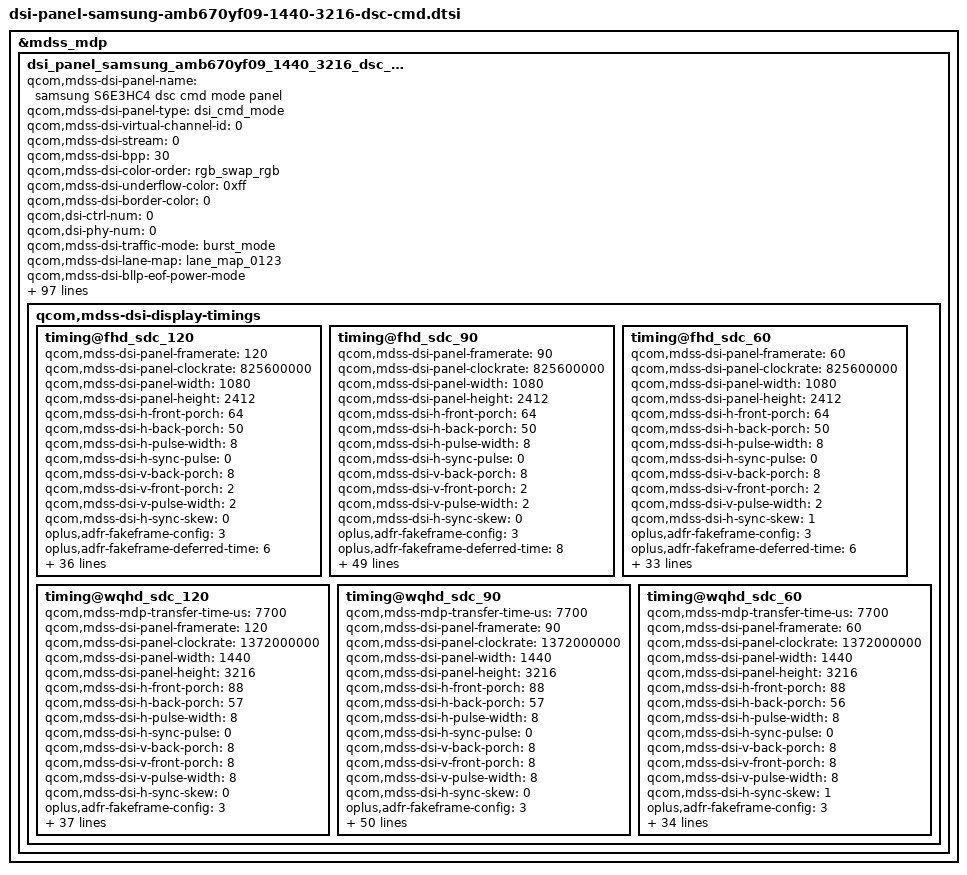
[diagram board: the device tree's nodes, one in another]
&mdss_mdp {
	dsi_panel_samsung_amb670yf09_1440_3216_dsc_cmd: qcom,mdss_dsi_panel_samsung_amb670yf09_1440_3216_dsc_cmd {
		qcom,mdss-dsi-panel-name = "samsung S6E3HC4 dsc cmd mode panel";
		qcom,mdss-dsi-panel-type = "dsi_cmd_mode";
		qcom,mdss-dsi-virtual-channel-id = <0>;
		qcom,mdss-dsi-stream = <0>;
		qcom,mdss-dsi-bpp = <30>;
		qcom,mdss-dsi-color-order = "rgb_swap_rgb";
		qcom,mdss-dsi-underflow-color = <0xff>;
		qcom,mdss-dsi-border-color = <0>;
		qcom,dsi-ctrl-num = <0>;
		qcom,dsi-phy-num = <0>;
		qcom,mdss-dsi-traffic-mode = "burst_mode";
		qcom,mdss-dsi-lane-map = "lane_map_0123";
		qcom,mdss-dsi-bllp-eof-power-mode;
		qcom,mdss-dsi-bllp-power-mode;
		qcom,mdss-dsi-lane-0-state;
		qcom,mdss-dsi-lane-1-state;
		qcom,mdss-dsi-lane-2-state;
		qcom,mdss-dsi-lane-3-state;
		qcom,mdss-dsi-dma-trigger = "trigger_sw";
		qcom,mdss-dsi-mdp-trigger = "none";
		qcom,mdss-dsi-reset-sequence = <1 10>, <0 5>, <1 10>;
		qcom,mdss-pan-physical-width-dimension = <73>;
		qcom,mdss-pan-physical-height-dimension = <160>;
		qcom,mdss-dsi-te-check-enable;
		qcom,mdss-dsi-te-using-te-pin;
		qcom,mdss-dsi-te-pin-select = <1>;
		qcom,mdss-dsi-te-dcs-command = <1>;
		qcom,mdss-dsi-wr-mem-start = <0x2C>;
		qcom,mdss-dsi-wr-mem-continue = <0x3C>;
		//qcom,mdss-dsi-lp11-init;
		qcom,mdss-dsi-init-delay-us = <1000>;
		qcom,mdss-dsi-panel-jitter = <0x4 0x1>;
		qcom,dynamic-mode-switch-enabled;
		qcom,dynamic-mode-switch-type = "dynamic-resolution-switch-immediate";
		/* HDR Setting */
		qcom,mdss-dsi-panel-hdr-enabled;
		qcom,mdss-dsi-panel-hdr-color-primaries = <15635 16450 34000 16000 13250 34500 7500 3000>;
		qcom,mdss-dsi-panel-peak-brightness = <5400000>;
		qcom,mdss-dsi-panel-average-brightness = <2000000>;
		qcom,mdss-dsi-panel-blackness-level = <2000>;

		qcom,mdss-dsi-display-timings {
			timing@fhd_sdc_120 {
				#include "dsi-panel-samsung-amb670yf09-1440-3216-dsc-cmd-common.dtsi"
				//qcom,mdss-mdp-transfer-time-us = <6000>;
				qcom,mdss-dsi-panel-framerate = <120>;
				qcom,mdss-dsi-panel-clockrate = <825600000>;
				qcom,mdss-dsi-panel-width = <1080>;
				qcom,mdss-dsi-panel-height = <2412>;
				qcom,mdss-dsi-h-front-porch = <64>;
				qcom,mdss-dsi-h-back-porch = <50>;
				qcom,mdss-dsi-h-pulse-width = <8>;
				qcom,mdss-dsi-h-sync-pulse = <0>;
				qcom,mdss-dsi-v-back-porch = <8>;
				qcom,mdss-dsi-v-front-porch = <2>;
				qcom,mdss-dsi-v-pulse-width = <2>;

				/* SDC ADFR */
				qcom,mdss-dsi-h-sync-skew = <0>;
				oplus,adfr-fakeframe-config = <3>;
				oplus,adfr-fakeframe-deferred-time = <6>;		/* period*0.7 */
				qcom,mdss-dsi-qsync-min-fps-0 = <1314>;
				qcom,mdss-dsi-qsync-min-fps-1 = <1314>;
				qcom,mdss-dsi-fakeframe-command = [
					05 00 00 40 00 00 01 2C
					05 00 00 40 00 00 01 3C
					05 00 00 40 00 00 01 2C
					05 00 00 40 00 00 01 3C
					05 00 00 00 00 00 01 00
				];

				qcom,mdss-dsi-timing-switch-command = [
					/* CASET/PASET Setting */
					39 00 00 00 00 00 05 2A 00 00 04 37
					39 00 00 00 00 00 05 2B 00 00 09 6B
					/* Scaler Setting */
					39 00 00 40 00 00 03 F0 5A 5A
					15 00 00 40 00 00 02 C3 89
					39 00 00 00 00 00 03 F0 A5 A5

					/* TSP_SYNC1 Fixed Setting */
					39 00 00 40 00 00 03 F0 5A 5A
					39 00 00 40 00 00 04 B0 00 3C B9
					39 00 00 40 00 00 03 B9 19 09
					39 00 00 40 00 00 04 B0 00 40 B9
					39 00 00 40 00 00 03 B9 33 33					/* TSP_VSYNC 0x33, 0x33 : Fixed TE; 0x30, 0x30 : G TE */
					39 00 00 40 00 00 04 B0 00 05 F2
					15 00 00 40 00 00 02 F2 C9
					15 00 00 40 00 00 02 F7 0F
					39 00 00 00 00 00 03 F0 A5 A5
					/* TSP_SYNC3 Fixed Setting */
					39 00 00 40 00 00 03 F0 5A 5A
					39 00 00 40 00 00 04 B0 00 06 F2
					15 00 00 40 00 00 02 F2 41
					39 00 00 40 00 00 04 B0 00 3E B9
					15 00 00 40 00 00 02 B9 09
					39 00 00 40 00 00 04 B0 00 42 B9
					15 00 00 40 00 00 02 B9 03
					39 00 00 40 00 00 04 B0 00 46 B9
					15 00 00 40 00 00 02 B9 00
					15 00 00 40 00 00 02 F7 0F
					39 00 00 00 79 00 03 F0 A5 A5
					/* Fixed TE Setting */
					39 00 00 40 00 00 03 F0 5A 5A
					15 00 00 40 00 00 02 B9 51
					39 00 00 40 00 00 04 B0 00 02 B9
					15 00 00 40 00 00 02 B9 00
					39 00 00 40 00 00 04 B0 00 08 B9
					39 00 00 40 00 00 09 B9 00 00 00 01 00 00 00 01
					39 00 00 00 79 00 03 F0 A5 A5

					/* 90hz Transition */
					39 00 00 40 00 00 03 F0 5A 5A
					15 00 00 40 00 00 02 AB 83
					39 00 00 40 00 00 04 B0 00 01 BD
					15 00 00 40 00 00 02 BD 02
					39 00 00 40 00 00 04 B0 00 08 F2
					39 00 00 40 00 00 04 F2 1C 00 14
					15 00 00 40 00 00 02 60 00
					15 00 00 40 00 00 02 F7 0F
					39 00 00 00 00 00 03 F0 A5 A5

					/* 120hz Transition */
					39 00 00 40 00 00 03 F0 5A 5A
					39 00 00 40 00 00 04 B0 00 17 F2
					39 00 00 40 00 00 03 F2 01 B5
					39 00 00 40 00 00 03 BD 21 02
					15 00 00 40 00 00 02 60 00
					39 00 00 40 00 00 04 B0 00 8C 94
					39 00 00 40 00 00 1F 94
						08 40 08 29 07 E2 07 B6
						07 53 06 EC 06 65 05 DB
						05 54 04 CD 04 4A 03 7C
						01 5E 01 5E 01 5E
					15 00 00 40 00 00 02 BD 23
					39 00 00 40 00 00 04 B0 00 10 BD
					15 00 00 40 00 00 02 BD 00
					39 00 00 40 00 00 04 B0 00 16 BD
					15 00 00 40 00 00 02 BD FF
					39 00 00 40 00 00 04 B0 00 14 BD
					15 00 00 40 00 00 02 BD 00
					15 00 00 40 00 00 02 F7 0F
					39 00 00 00 00 00 03 F0 A5 A5
				];
				qcom,mdss-dsi-on-command = [
					/* DSC Setting */
					39 00 00 00 00 00 5A 9E
						12 00 00 AB 30 80 09 6C
						04 38 00 24 02 1C 02 1C
						02 00 02 3B 00 20 03 35
						00 07 00 0E 03 34 02 D4
						18 00 10 F0 07 10 20 00
						06 0F 0F 33 0E 1C 2A 38
						46 54 62 69 70 77 79 7B
						7D 7E 02 02 22 00 2A 40
						2A BE 3A FC 3A FA 3A F8
						3B 38 3B 78 3B B6 4B B6
						4B F4 4B F4 6C 34 84 74
						00
					15 00 00 00 00 00 02 9D 01

					/* Sleep Out(11h) */
					05 00 00 00 06 00 01 11

					/* TSP_SYNC1 Fixed Setting */
					39 00 00 40 00 00 03 F0 5A 5A
					39 00 00 40 00 00 04 B0 00 3C B9
					39 00 00 40 00 00 03 B9 19 09
					39 00 00 40 00 00 04 B0 00 40 B9
					39 00 00 40 00 00 03 B9 33 33					/* TSP_VSYNC 0x33, 0x33 : Fixed TE; 0x30, 0x30 : G TE */
					39 00 00 40 00 00 04 B0 00 05 F2
					15 00 00 40 00 00 02 F2 C9
					15 00 00 40 00 00 02 F7 0F
					39 00 00 00 00 00 03 F0 A5 A5
					/* TSP_SYNC3 Fixed Setting */
					39 00 00 40 00 00 03 F0 5A 5A
					39 00 00 40 00 00 04 B0 00 06 F2
					15 00 00 40 00 00 02 F2 41
					39 00 00 40 00 00 04 B0 00 3E B9
					15 00 00 40 00 00 02 B9 09
					39 00 00 40 00 00 04 B0 00 42 B9
					15 00 00 40 00 00 02 B9 03
					39 00 00 40 00 00 04 B0 00 46 B9
					15 00 00 40 00 00 02 B9 00
					15 00 00 40 00 00 02 F7 0F
					39 00 00 00 79 00 03 F0 A5 A5
					/* Fixed TE Setting */
					39 00 00 40 00 00 03 F0 5A 5A
					15 00 00 40 00 00 02 B9 51
					39 00 00 40 00 00 04 B0 00 02 B9
					15 00 00 40 00 00 02 B9 00
					39 00 00 40 00 00 04 B0 00 08 B9
					39 00 00 40 00 00 09 B9 00 00 00 01 00 00 00 01
					39 00 00 00 79 00 03 F0 A5 A5

					/* 90hz Transition */
					39 00 00 40 00 00 03 F0 5A 5A
					15 00 00 40 00 00 02 AB 83
					39 00 00 40 00 00 04 B0 00 01 BD
					15 00 00 40 00 00 02 BD 02
					39 00 00 40 00 00 04 B0 00 08 F2
					39 00 00 40 00 00 04 F2 1C 00 14
					15 00 00 40 00 00 02 60 00
					15 00 00 40 00 00 02 F7 0F
					39 00 00 00 00 00 03 F0 A5 A5

					/* 120hz Transition */
					39 00 00 40 00 00 03 F0 5A 5A
					39 00 00 40 00 00 04 B0 00 17 F2
					39 00 00 40 00 00 03 F2 01 B5
					39 00 00 40 00 00 03 BD 21 02
					15 00 00 40 00 00 02 60 00
					39 00 00 40 00 00 04 B0 00 8C 94
					39 00 00 40 00 00 1F 94
						08 40 08 29 07 E2 07 B6
						07 53 06 EC 06 65 05 DB
						05 54 04 CD 04 4A 03 7C
						01 5E 01 5E 01 5E
					15 00 00 40 00 00 02 BD 23
					39 00 00 40 00 00 04 B0 00 10 BD
					15 00 00 40 00 00 02 BD 00
					39 00 00 40 00 00 04 B0 00 16 BD
					15 00 00 40 00 00 02 BD FF
					39 00 00 40 00 00 04 B0 00 14 BD
					15 00 00 40 00 00 02 BD 00
					15 00 00 40 00 00 02 F7 0F
					39 00 00 00 00 00 03 F0 A5 A5

					/* Common Setting */
					39 00 00 40 00 00 03 F0 5A 5A
					39 00 00 40 00 00 03 F2 00 01					/* FQ_CON Setting */
					39 00 00 00 00 00 03 F0 A5 A5
					/* TE(Vsync) ON */
					39 00 00 40 00 00 03 F0 5A 5A
					15 00 00 40 00 00 02 35 00
					39 00 00 00 00 00 03 F0 A5 A5
					/* CASET/PASET Setting */
					39 00 00 00 00 00 05 2A 00 00 04 37
					39 00 00 00 00 00 05 2B 00 00 09 6B
					/* Scaler Setting */
					39 00 00 40 00 00 03 F0 5A 5A
					15 00 00 40 00 00 02 C3 89
					39 00 00 00 00 00 03 F0 A5 A5
					/* DCDC setting of AOD Sequence */
					39 00 00 40 00 00 03 F0 5A 5A
					39 00 00 40 00 00 04 B0 00 18 B1
					15 00 00 40 00 00 02 B1 05
					39 00 00 00 00 00 03 F0 A5 A5

					/* Brightness Control */
					39 00 00 40 00 00 03 F0 5A 5A
					39 00 00 40 00 00 04 B0 00 10 94
					15 00 00 40 00 00 02 94 01
					39 00 00 40 00 00 04 B0 00 0F 94
					15 00 00 40 00 00 02 94 90
					39 00 00 40 00 00 03 F0 A5 A5
					15 00 00 40 00 00 02 53 28
					15 00 00 00 00 00 02 F7 0F
					/* ACL Mode */
					39 00 00 40 00 00 03 F0 5A 5A
					39 00 00 40 00 00 04 B0 00 01 94
					15 00 00 40 00 00 02 94 0D
					15 00 00 40 00 00 02 55 00
					39 00 00 00 00 00 03 F0 A5 A5
					/* OPEC Setting */
					39 00 00 40 00 00 03 F0 5A 5A
					39 00 00 40 00 00 04 B0 00 1D 63
					15 00 00 40 00 00 02 63 02
					39 00 00 00 00 00 03 F0 A5 A5
					/* Display On */
					05 00 00 00 00 00 01 29
				];

				qcom,mdss-dsi-qsync-on-commands = [
					/* SDC Auto On */
					39 00 00 40 00 00 03 F0 5A 5A
					15 00 00 40 00 00 02 BD 23
					39 00 00 40 00 00 04 B0 00 10 BD
					15 00 00 40 00 00 02 BD 10
					39 00 00 40 00 00 04 B0 00 16 BD
					15 00 00 40 00 00 02 BD 03
					15 00 00 40 00 00 02 F7 0F
					39 00 00 00 00 00 03 F0 A5 A5
				];
				qcom,mdss-dsi-qsync-off-commands = [
					/* SDC Auto Off */
					39 00 00 40 00 00 03 F0 5A 5A
					15 00 00 40 00 00 02 BD 23
					39 00 00 40 00 00 04 B0 00 10 BD
					15 00 00 40 00 00 02 BD 00
					39 00 00 40 00 00 04 B0 00 16 BD
					15 00 00 40 00 00 02 BD FF
					15 00 00 40 00 00 02 F7 0F
					39 00 00 00 00 00 03 F0 A5 A5
				];
				qcom,mdss-dsi-qsync-min-fps-0-command = [
					/* SDC Auto Off */
					39 00 00 40 00 00 03 F0 5A 5A
					39 00 00 40 00 00 04 B0 00 14 BD
					15 00 00 40 00 00 02 BD 00
					39 00 00 40 00 00 04 B0 00 13 BD
					15 00 00 40 00 00 02 BD 00
					15 00 00 40 00 00 02 F7 0F
					39 00 00 00 00 00 03 F0 A5 A5
				];
				qcom,mdss-dsi-qsync-min-fps-1-command = [
					/* SDC Auto On */
					39 00 00 40 00 00 03 F0 5A 5A
					39 00 00 40 00 00 04 B0 00 14 BD
					15 00 00 40 00 00 02 BD 00
					39 00 00 40 00 00 04 B0 00 13 BD
					15 00 00 40 00 00 02 BD 00
					15 00 00 40 00 00 02 F7 0F
					39 00 00 00 00 00 03 F0 A5 A5
				];

				qcom,mdss-dsi-fakeframe-command-state = "dsi_hs_mode";
				qcom,mdss-dsi-qsync-on-commands-state ="dsi_hs_mode";
				qcom,mdss-dsi-qsync-off-commands-state ="dsi_hs_mode";
				qcom,mdss-dsi-qsync-min-fps-0-command-state = "dsi_hs_mode";
				qcom,mdss-dsi-qsync-min-fps-1-command-state = "dsi_hs_mode";
				qcom,panel-roi-alignment=<1080 36 1080 36 1080 36>;
				qcom,partial-update-enabled = "single_roi";

				qcom,lm-split = <540 540>;
				qcom,mdss-dsc-slice-height = <36>;
				qcom,mdss-dsc-slice-width = <540>;
			};

			timing@fhd_sdc_90 {
				//qcom,mdss-mdp-transfer-time-us = <6000>;
				qcom,mdss-dsi-panel-framerate = <90>;
				qcom,mdss-dsi-panel-clockrate = <825600000>;
				qcom,mdss-dsi-panel-width = <1080>;
				qcom,mdss-dsi-panel-height = <2412>;
				qcom,mdss-dsi-h-front-porch = <64>;
				qcom,mdss-dsi-h-back-porch = <50>;
				qcom,mdss-dsi-h-pulse-width = <8>;
				qcom,mdss-dsi-h-sync-pulse = <0>;
				qcom,mdss-dsi-v-back-porch = <8>;
				qcom,mdss-dsi-v-front-porch = <2>;
				qcom,mdss-dsi-v-pulse-width = <2>;

				/* SDC ADFR */
				qcom,mdss-dsi-h-sync-skew = <0>;
				oplus,adfr-fakeframe-config = <3>;
				oplus,adfr-fakeframe-deferred-time = <8>;		/* period*0.7 */
				qcom,mdss-dsi-qsync-min-fps-0 = <1314>;
				qcom,mdss-dsi-qsync-min-fps-1 = <1314>;
				qcom,mdss-dsi-fakeframe-command = [
					05 00 00 40 00 00 01 2C
					05 00 00 40 00 00 01 3C
					05 00 00 40 00 00 01 2C
					05 00 00 40 00 00 01 3C
					05 00 00 00 00 00 01 00
				];

				qcom,mdss-dsi-adfr-pre-switch-command = [
					39 00 00 40 00 00 03 F0 5A 5A					/* Level2 key Access Enable */
					39 00 00 40 00 00 04 B0 00 14 BD
					15 00 00 40 00 00 02 BD 00						/* SDC auto mode min == max */
					15 00 00 40 00 00 02 BD 23						/* 21 : Manual On  23 Auto On */
					15 00 00 40 00 00 02 F7 0F
					39 00 00 00 00 00 03 F0 A5 A5					/* Level2 key Access Disable */
				];

				qcom,mdss-dsi-timing-switch-command = [
					/* CASET/PASET Setting */
					39 00 00 00 00 00 05 2A 00 00 04 37
					39 00 00 00 00 00 05 2B 00 00 09 6B
					/* Scaler Setting */
					39 00 00 40 00 00 03 F0 5A 5A
					15 00 00 40 00 00 02 C3 89
					39 00 00 00 00 00 03 F0 A5 A5

					/* TSP_SYNC1 Fixed Setting */
					39 00 00 40 00 00 03 F0 5A 5A
					39 00 00 40 00 00 04 B0 00 3C B9
					39 00 00 40 00 00 03 B9 19 09
					39 00 00 40 00 00 04 B0 00 40 B9
					39 00 00 40 00 00 03 B9 33 33					/* TSP_VSYNC 0x33, 0x33 : Fixed TE; 0x30, 0x30 : G TE */
					39 00 00 40 00 00 04 B0 00 05 F2
					15 00 00 40 00 00 02 F2 C9
					15 00 00 40 00 00 02 F7 0F
					39 00 00 00 00 00 03 F0 A5 A5
					/* TSP_SYNC3 Fixed Setting */
					39 00 00 40 00 00 03 F0 5A 5A
					39 00 00 40 00 00 04 B0 00 06 F2
					15 00 00 40 00 00 02 F2 41
					39 00 00 40 00 00 04 B0 00 3E B9
					15 00 00 40 00 00 02 B9 09
					39 00 00 40 00 00 04 B0 00 42 B9
					15 00 00 40 00 00 02 B9 03
					39 00 00 40 00 00 04 B0 00 46 B9
					15 00 00 40 00 00 02 B9 00
					15 00 00 40 00 00 02 F7 0F
					39 00 00 00 79 00 03 F0 A5 A5

					/* 120hz Transition */
					39 00 00 40 00 00 03 F0 5A 5A
					39 00 00 40 00 00 04 B0 00 17 F2
					39 00 00 40 00 00 03 F2 01 B5
					39 00 00 40 00 00 03 BD 21 02
					15 00 00 40 00 00 02 60 00
					39 00 00 40 00 00 04 B0 00 8C 94
					39 00 00 40 00 00 1F 94
						08 40 08 29 07 E2 07 B6
						07 53 06 EC 06 65 05 DB
						05 54 04 CD 04 4A 03 7C
						01 5E 01 5E 01 5E
					15 00 00 40 00 00 02 F7 0F
					39 00 00 00 00 00 03 F0 A5 A5

					/* 90hz Transition */
					39 00 00 40 00 00 03 F0 5A 5A
					15 00 00 40 00 00 02 AB 83
					39 00 00 40 00 00 04 B0 00 01 BD
					15 00 00 40 00 00 02 BD 03
					39 00 00 40 00 00 04 B0 00 08 F2
					39 00 00 40 00 00 04 F2 1C 04 54
					15 00 00 40 00 00 02 60 08
					15 00 00 40 00 00 02 F7 0F
					39 00 00 00 00 00 03 F0 A5 A5
				];
				qcom,mdss-dsi-on-command = [
					/* DSC Setting */
					39 00 00 00 00 00 5A 9E
						12 00 00 AB 30 80 09 6C
						04 38 00 24 02 1C 02 1C
						02 00 02 3B 00 20 03 35
						00 07 00 0E 03 34 02 D4
						18 00 10 F0 07 10 20 00
						06 0F 0F 33 0E 1C 2A 38
						46 54 62 69 70 77 79 7B
						7D 7E 02 02 22 00 2A 40
						2A BE 3A FC 3A FA 3A F8
						3B 38 3B 78 3B B6 4B B6
						4B F4 4B F4 6C 34 84 74
						00
					15 00 00 00 00 00 02 9D 01

					/* Sleep Out(11h) */
					05 00 00 00 06 00 01 11

					/* TSP_SYNC1 Fixed Setting */
					39 00 00 40 00 00 03 F0 5A 5A
					39 00 00 40 00 00 04 B0 00 3C B9
					39 00 00 40 00 00 03 B9 19 09
					39 00 00 40 00 00 04 B0 00 40 B9
					39 00 00 40 00 00 03 B9 33 33					/* TSP_VSYNC 0x33, 0x33 : Fixed TE; 0x30, 0x30 : G TE */
					39 00 00 40 00 00 04 B0 00 05 F2
					15 00 00 40 00 00 02 F2 C9
					15 00 00 40 00 00 02 F7 0F
					39 00 00 00 00 00 03 F0 A5 A5
					/* TSP_SYNC3 Fixed Setting */
					39 00 00 40 00 00 03 F0 5A 5A
					39 00 00 40 00 00 04 B0 00 06 F2
					15 00 00 40 00 00 02 F2 41
					39 00 00 40 00 00 04 B0 00 3E B9
					15 00 00 40 00 00 02 B9 09
					39 00 00 40 00 00 04 B0 00 42 B9
					15 00 00 40 00 00 02 B9 03
					39 00 00 40 00 00 04 B0 00 46 B9
					15 00 00 40 00 00 02 B9 00
					15 00 00 40 00 00 02 F7 0F
					39 00 00 00 79 00 03 F0 A5 A5

					/* 120hz Transition */
					39 00 00 40 00 00 03 F0 5A 5A
					39 00 00 40 00 00 04 B0 00 17 F2
					39 00 00 40 00 00 03 F2 01 B5
					39 00 00 40 00 00 03 BD 21 02
					15 00 00 40 00 00 02 60 00
					39 00 00 40 00 00 04 B0 00 8C 94
					39 00 00 40 00 00 1F 94
						08 40 08 29 07 E2 07 B6
						07 53 06 EC 06 65 05 DB
						05 54 04 CD 04 4A 03 7C
						01 5E 01 5E 01 5E
					15 00 00 40 00 00 02 F7 0F
					39 00 00 00 00 00 03 F0 A5 A5

					/* 90hz Transition */
					39 00 00 40 00 00 03 F0 5A 5A
					15 00 00 40 00 00 02 AB 83
					39 00 00 40 00 00 04 B0 00 01 BD
					15 00 00 40 00 00 02 BD 03
					39 00 00 40 00 00 04 B0 00 08 F2
					39 00 00 40 00 00 04 F2 1C 04 54
					15 00 00 40 00 00 02 60 08
					15 00 00 40 00 00 02 F7 0F
					39 00 00 00 00 00 03 F0 A5 A5

					/* Common Setting */
					39 00 00 40 00 00 03 F0 5A 5A
					39 00 00 40 00 00 03 F2 00 01					/* FQ_CON Setting */
					39 00 00 00 00 00 03 F0 A5 A5
					/* TE(Vsync) ON */
					39 00 00 40 00 00 03 F0 5A 5A
					15 00 00 40 00 00 02 35 00
					39 00 00 00 00 00 03 F0 A5 A5
					/* CASET/PASET Setting */
					39 00 00 00 00 00 05 2A 00 00 04 37
					39 00 00 00 00 00 05 2B 00 00 09 6B
					/* Scaler Setting */
					39 00 00 40 00 00 03 F0 5A 5A
					15 00 00 40 00 00 02 C3 89
					39 00 00 00 00 00 03 F0 A5 A5
					/* DCDC setting of AOD Sequence */
					39 00 00 40 00 00 03 F0 5A 5A
					39 00 00 40 00 00 04 B0 00 18 B1
					15 00 00 40 00 00 02 B1 05
					39 00 00 00 00 00 03 F0 A5 A5

					/* Brightness Control */
					39 00 00 40 00 00 03 F0 5A 5A
					39 00 00 40 00 00 04 B0 00 10 94
					15 00 00 40 00 00 02 94 01
					39 00 00 40 00 00 04 B0 00 0F 94
					15 00 00 40 00 00 02 94 90
					39 00 00 40 00 00 03 F0 A5 A5
					15 00 00 40 00 00 02 53 28
					15 00 00 00 00 00 02 F7 0F
					/* ACL Mode */
					39 00 00 40 00 00 03 F0 5A 5A
					39 00 00 40 00 00 04 B0 00 01 94
					15 00 00 40 00 00 02 94 0D
					15 00 00 40 00 00 02 55 00
					39 00 00 00 00 00 03 F0 A5 A5
					/* OPEC Setting */
					39 00 00 40 00 00 03 F0 5A 5A
					39 00 00 40 00 00 04 B0 00 1D 63
					15 00 00 40 00 00 02 63 02
					39 00 00 00 00 00 03 F0 A5 A5
					/* Display On */
					05 00 00 00 00 00 01 29
				];

				qcom,mdss-dsi-post-on-backlight = [
					/* Display On */
					05 00 00 00 00 00 01 29
				];
				qcom,mdss-dsi-off-command = [
					/* Display Off */
					05 00 00 00 15 00 02 28 00
					/* Sleep In */
					05 00 00 00 65 00 02 10 00
				];

				qcom,mdss-dsi-qsync-on-commands = [
				];
				qcom,mdss-dsi-qsync-off-commands = [
				];
				qcom,mdss-dsi-qsync-min-fps-0-command = [
				];
				qcom,mdss-dsi-qsync-min-fps-1-command = [
				];

				qcom,mdss-dsi-fakeframe-command-state = "dsi_hs_mode";
				qcom,mdss-dsi-adfr-pre-switch-command-state = "dsi_hs_mode";
				qcom,mdss-dsi-timing-switch-command-state = "dsi_hs_mode";
				qcom,mdss-dsi-qsync-on-commands-state ="dsi_hs_mode";
				qcom,mdss-dsi-qsync-off-commands-state ="dsi_hs_mode";
				qcom,mdss-dsi-qsync-min-fps-0-command-state = "dsi_hs_mode";
				qcom,mdss-dsi-qsync-min-fps-1-command-state = "dsi_hs_mode";
				qcom,panel-roi-alignment=<1080 36 1080 36 1080 36>;
				qcom,partial-update-enabled = "single_roi";

				qcom,compression-mode = "dsc";
				qcom,mdss-dsc-encoders = <2>;
				qcom,mdss-dsc-slice-per-pkt = <2>;
				qcom,mdss-dsc-bit-per-component = <10>;
				qcom,mdss-dsc-bit-per-pixel = <8>;
				qcom,mdss-dsc-version = <0x12>;
				//qcom,mdss-dsc-scr-version = <1>;
				qcom,mdss-dsc-block-prediction-enable;
				qcom,lm-split = <540 540>;
				qcom,mdss-dsc-slice-height = <36>;
				qcom,mdss-dsc-slice-width = <540>;
			};

			timing@fhd_sdc_60 {
				#include "dsi-panel-samsung-amb670yf09-1440-3216-dsc-60fps-cmd-common.dtsi"
				//qcom,mdss-mdp-transfer-time-us = <6000>;
				qcom,mdss-dsi-panel-framerate = <60>;
				qcom,mdss-dsi-panel-clockrate = <825600000>;
				qcom,mdss-dsi-panel-width = <1080>;
				qcom,mdss-dsi-panel-height = <2412>;
				qcom,mdss-dsi-h-front-porch = <64>;
				qcom,mdss-dsi-h-back-porch = <50>;
				qcom,mdss-dsi-h-pulse-width = <8>;
				qcom,mdss-dsi-h-sync-pulse = <0>;
				qcom,mdss-dsi-v-back-porch = <8>;
				qcom,mdss-dsi-v-front-porch = <2>;
				qcom,mdss-dsi-v-pulse-width = <2>;

				/* SDC ADFR */
				qcom,mdss-dsi-h-sync-skew = <1>;
				oplus,adfr-fakeframe-config = <3>;
				oplus,adfr-fakeframe-deferred-time = <6>;		/* period*0.7 */
				qcom,mdss-dsi-qsync-min-fps-0 = <1314>;
				qcom,mdss-dsi-qsync-min-fps-1 = <1314>;
				qcom,mdss-dsi-fakeframe-command = [
					05 00 00 40 00 00 01 2C
					05 00 00 40 00 00 01 3C
					05 00 00 40 00 00 01 2C
					05 00 00 40 00 00 01 3C
					05 00 00 00 00 00 01 00
				];

				qcom,mdss-dsi-timing-switch-command = [
					/* CASET/PASET Setting */
					39 00 00 00 00 00 05 2A 00 00 04 37
					39 00 00 00 00 00 05 2B 00 00 09 6B
					/* Scaler Setting */
					39 00 00 40 00 00 03 F0 5A 5A
					15 00 00 40 00 00 02 C3 89
					39 00 00 00 00 00 03 F0 A5 A5

					/* TSP_SYNC1 Fixed Setting */
					39 00 00 40 00 00 03 F0 5A 5A
					39 00 00 40 00 00 04 B0 00 3C B9
					39 00 00 40 00 00 03 B9 19 09
					39 00 00 40 00 00 04 B0 00 40 B9
					39 00 00 40 00 00 03 B9 33 33					/* TSP_VSYNC 0x33, 0x33 : Fixed TE; 0x30, 0x30 : G TE */
					39 00 00 40 00 00 04 B0 00 05 F2
					15 00 00 40 00 00 02 F2 C9
					15 00 00 40 00 00 02 F7 0F
					39 00 00 00 00 00 03 F0 A5 A5
					/* TSP_SYNC3 Fixed Setting */
					39 00 00 40 00 00 03 F0 5A 5A
					39 00 00 40 00 00 04 B0 00 06 F2
					15 00 00 40 00 00 02 F2 41
					39 00 00 40 00 00 04 B0 00 3E B9
					15 00 00 40 00 00 02 B9 09
					39 00 00 40 00 00 04 B0 00 42 B9
					15 00 00 40 00 00 02 B9 03
					39 00 00 40 00 00 04 B0 00 46 B9
					15 00 00 40 00 00 02 B9 01
					15 00 00 40 00 00 02 F7 0F
					39 00 00 00 79 00 03 F0 A5 A5
					/* Fixed TE Setting */
					39 00 00 40 00 00 03 F0 5A 5A
					15 00 00 40 00 00 02 B9 51
					39 00 00 40 00 00 04 B0 00 02 B9
					15 00 00 40 00 00 02 B9 01
					39 00 00 40 00 00 04 B0 00 08 B9
					39 00 00 40 00 00 09 B9 00 00 00 01 00 00 00 01
					39 00 00 00 79 00 03 F0 A5 A5

					/* 90hz Transition */
					39 00 00 40 00 00 03 F0 5A 5A
					15 00 00 40 00 00 02 AB 83
					39 00 00 40 00 00 04 B0 00 01 BD
					15 00 00 40 00 00 02 BD 02
					39 00 00 40 00 00 04 B0 00 08 F2
					39 00 00 40 00 00 04 F2 1C 00 14
					15 00 00 40 00 00 02 60 00
					15 00 00 40 00 00 02 F7 0F
					39 00 00 00 00 00 03 F0 A5 A5

					/* 60hz Transition */
					39 00 00 40 00 00 03 F0 5A 5A
					39 00 00 40 00 00 04 B0 00 17 F2
					39 00 00 40 00 00 03 F2 01 B5
					39 00 00 40 00 00 03 BD 21 02
					15 00 00 40 00 00 02 60 01
					39 00 00 40 00 00 04 B0 00 8C 94
					39 00 00 40 00 00 1F 94
						08 40 08 29 07 E2 07 B6
						07 53 06 EC 06 65 05 DB
						05 54 04 CD 04 4A 03 7C
						01 5E 01 5E 01 5E
					15 00 00 40 00 00 02 BD 23
					39 00 00 40 00 00 04 B0 00 10 BD
					15 00 00 40 00 00 02 BD 00
					39 00 00 40 00 00 04 B0 00 16 BD
					15 00 00 40 00 00 02 BD FF
					39 00 00 40 00 00 04 B0 00 14 BD
					15 00 00 40 00 00 02 BD 01
					15 00 00 40 00 00 02 F7 0F
					39 00 00 00 00 00 03 F0 A5 A5
				];
				qcom,mdss-dsi-on-command = [
					/* DSC Setting */
					39 00 00 00 00 00 5A 9E
						12 00 00 AB 30 80 09 6C
						04 38 00 24 02 1C 02 1C
						02 00 02 3B 00 20 03 35
						00 07 00 0E 03 34 02 D4
						18 00 10 F0 07 10 20 00
						06 0F 0F 33 0E 1C 2A 38
						46 54 62 69 70 77 79 7B
						7D 7E 02 02 22 00 2A 40
						2A BE 3A FC 3A FA 3A F8
						3B 38 3B 78 3B B6 4B B6
						4B F4 4B F4 6C 34 84 74
						00
					15 00 00 00 00 00 02 9D 01

					/* Sleep Out(11h) */
					05 00 00 00 06 00 01 11

					/* TSP_SYNC1 Fixed Setting */
					39 00 00 40 00 00 03 F0 5A 5A
					39 00 00 40 00 00 04 B0 00 3C B9
					39 00 00 40 00 00 03 B9 19 09
					39 00 00 40 00 00 04 B0 00 40 B9
					39 00 00 40 00 00 03 B9 33 33					/* TSP_VSYNC 0x33, 0x33 : Fixed TE; 0x30, 0x30 : G TE */
					39 00 00 40 00 00 04 B0 00 05 F2
					15 00 00 40 00 00 02 F2 C9
					15 00 00 40 00 00 02 F7 0F
					39 00 00 00 00 00 03 F0 A5 A5
					/* TSP_SYNC3 Fixed Setting */
					39 00 00 40 00 00 03 F0 5A 5A
					39 00 00 40 00 00 04 B0 00 06 F2
					15 00 00 40 00 00 02 F2 41
					39 00 00 40 00 00 04 B0 00 3E B9
					15 00 00 40 00 00 02 B9 09
					39 00 00 40 00 00 04 B0 00 42 B9
					15 00 00 40 00 00 02 B9 03
					39 00 00 40 00 00 04 B0 00 46 B9
					15 00 00 40 00 00 02 B9 01
					15 00 00 40 00 00 02 F7 0F
					39 00 00 00 79 00 03 F0 A5 A5
					/* Fixed TE Setting */
					39 00 00 40 00 00 03 F0 5A 5A
					15 00 00 40 00 00 02 B9 51
					39 00 00 40 00 00 04 B0 00 02 B9
					15 00 00 40 00 00 02 B9 01
					39 00 00 40 00 00 04 B0 00 08 B9
					39 00 00 40 00 00 09 B9 00 00 00 01 00 00 00 01
					39 00 00 00 79 00 03 F0 A5 A5

					/* 90hz Transition */
					39 00 00 40 00 00 03 F0 5A 5A
					15 00 00 40 00 00 02 AB 83
					39 00 00 40 00 00 04 B0 00 01 BD
					15 00 00 40 00 00 02 BD 02
					39 00 00 40 00 00 04 B0 00 08 F2
					39 00 00 40 00 00 04 F2 1C 00 14
					15 00 00 40 00 00 02 60 00
					15 00 00 40 00 00 02 F7 0F
					39 00 00 00 00 00 03 F0 A5 A5

					/* 60hz Transition */
					39 00 00 40 00 00 03 F0 5A 5A
					39 00 00 40 00 00 04 B0 00 17 F2
					39 00 00 40 00 00 03 F2 01 B5
					39 00 00 40 00 00 03 BD 21 02
					15 00 00 40 00 00 02 60 01
					39 00 00 40 00 00 04 B0 00 8C 94
					39 00 00 40 00 00 1F 94
						08 40 08 29 07 E2 07 B6
						07 53 06 EC 06 65 05 DB
						05 54 04 CD 04 4A 03 7C
						01 5E 01 5E 01 5E
					15 00 00 40 00 00 02 BD 23
					39 00 00 40 00 00 04 B0 00 10 BD
					15 00 00 40 00 00 02 BD 00
					39 00 00 40 00 00 04 B0 00 16 BD
					15 00 00 40 00 00 02 BD FF
					39 00 00 40 00 00 04 B0 00 14 BD
					15 00 00 40 00 00 02 BD 01
					15 00 00 40 00 00 02 F7 0F
					39 00 00 00 00 00 03 F0 A5 A5

					/* Common Setting */
					39 00 00 40 00 00 03 F0 5A 5A
					39 00 00 40 00 00 03 F2 00 01					/* FQ_CON Setting */
					39 00 00 00 00 00 03 F0 A5 A5
					/* TE(Vsync) ON */
					39 00 00 40 00 00 03 F0 5A 5A
					15 00 00 40 00 00 02 35 00
					39 00 00 00 00 00 03 F0 A5 A5
					/* CASET/PASET Setting */
					39 00 00 00 00 00 05 2A 00 00 04 37
					39 00 00 00 00 00 05 2B 00 00 09 6B
					/* Scaler Setting */
					39 00 00 40 00 00 03 F0 5A 5A
					15 00 00 40 00 00 02 C3 89
					39 00 00 00 00 00 03 F0 A5 A5
					/* DCDC setting of AOD Sequence */
					39 00 00 40 00 00 03 F0 5A 5A
					39 00 00 40 00 00 04 B0 00 18 B1
					15 00 00 40 00 00 02 B1 05
					39 00 00 00 00 00 03 F0 A5 A5

					/* Brightness Control */
					39 00 00 40 00 00 03 F0 5A 5A
					39 00 00 40 00 00 04 B0 00 10 94
					15 00 00 40 00 00 02 94 01
					39 00 00 40 00 00 04 B0 00 0F 94
					15 00 00 40 00 00 02 94 90
					39 00 00 40 00 00 03 F0 A5 A5
					15 00 00 40 00 00 02 53 28
					15 00 00 00 00 00 02 F7 0F
					/* ACL Mode */
					39 00 00 40 00 00 03 F0 5A 5A
					39 00 00 40 00 00 04 B0 00 01 94
					15 00 00 40 00 00 02 94 0D
					15 00 00 40 00 00 02 55 00
					39 00 00 00 00 00 03 F0 A5 A5
					/* OPEC Setting */
					39 00 00 40 00 00 03 F0 5A 5A
					39 00 00 40 00 00 04 B0 00 1D 63
					15 00 00 40 00 00 02 63 02
					39 00 00 00 00 00 03 F0 A5 A5
					/* Display On */
					05 00 00 00 00 00 01 29
				];

				qcom,mdss-dsi-qsync-on-commands = [
				];
				qcom,mdss-dsi-qsync-off-commands = [
					/* SDC Auto Off */
					39 00 00 40 00 00 03 F0 5A 5A
					15 00 00 40 00 00 02 BD 23
					39 00 00 40 00 00 04 B0 00 10 BD
					15 00 00 40 00 00 02 BD 00
					39 00 00 40 00 00 04 B0 00 16 BD
					15 00 00 40 00 00 02 BD FF
					15 00 00 40 00 00 02 F7 0F
					39 00 00 00 00 00 03 F0 A5 A5
				];
				qcom,mdss-dsi-qsync-min-fps-0-command = [
					/* SDC Auto Off */
					39 00 00 40 00 00 03 F0 5A 5A
					39 00 00 40 00 00 04 B0 00 14 BD
					15 00 00 40 00 00 02 BD 00
					39 00 00 40 00 00 04 B0 00 13 BD
					15 00 00 40 00 00 02 BD 00
					15 00 00 40 00 00 02 F7 0F
					39 00 00 00 00 00 03 F0 A5 A5
				];

				qcom,mdss-dsi-fakeframe-command-state = "dsi_hs_mode";
				qcom,mdss-dsi-qsync-on-commands-state ="dsi_hs_mode";
				qcom,mdss-dsi-qsync-off-commands-state ="dsi_hs_mode";
				qcom,mdss-dsi-qsync-min-fps-0-command-state = "dsi_hs_mode";
				qcom,mdss-dsi-qsync-min-fps-1-command-state = "dsi_hs_mode";
				qcom,panel-roi-alignment=<1080 36 1080 36 1080 36>;
				qcom,partial-update-enabled = "single_roi";

				qcom,lm-split = <540 540>;
				qcom,mdss-dsc-slice-height = <36>;
				qcom,mdss-dsc-slice-width = <540>;
			};

			timing@wqhd_sdc_120 {
				#include "dsi-panel-samsung-amb670yf09-1440-3216-dsc-cmd-common.dtsi"
				qcom,mdss-mdp-transfer-time-us = <7700>;
				qcom,mdss-dsi-panel-framerate = <120>;
				qcom,mdss-dsi-panel-clockrate = <1372000000>;
				qcom,mdss-dsi-panel-width = <1440>;
				qcom,mdss-dsi-panel-height = <3216>;
				qcom,mdss-dsi-h-front-porch = <88>;
				qcom,mdss-dsi-h-back-porch = <57>;
				qcom,mdss-dsi-h-pulse-width = <8>;
				qcom,mdss-dsi-h-sync-pulse = <0>;
				qcom,mdss-dsi-v-back-porch = <8>;
				qcom,mdss-dsi-v-front-porch = <8>;
				qcom,mdss-dsi-v-pulse-width = <8>;


				/* SDC ADFR */
				qcom,mdss-dsi-h-sync-skew = <0>;
				oplus,adfr-fakeframe-config = <3>;
				oplus,adfr-fakeframe-deferred-time = <6>;		/* period*0.7 */
				qcom,mdss-dsi-qsync-min-fps-0 = <1314>;
				qcom,mdss-dsi-qsync-min-fps-1 = <1314>;
				qcom,mdss-dsi-fakeframe-command = [
					05 00 00 40 00 00 01 2C
					05 00 00 40 00 00 01 3C
					05 00 00 40 00 00 01 2C
					05 00 00 40 00 00 01 3C
					05 00 00 00 00 00 01 00
				];

				qcom,mdss-dsi-timing-switch-command = [
					/* CASET/PASET Setting */
					39 00 00 00 00 00 05 2A 00 00 05 9F
					39 00 00 00 00 00 05 2B 00 00 0C 8F
					/* Scaler Setting */
					39 00 00 40 00 00 03 F0 5A 5A
					15 00 00 40 00 00 02 C3 00
					39 00 00 00 00 00 03 F0 A5 A5

					/* TSP_SYNC1 Fixed Setting */
					39 00 00 40 00 00 03 F0 5A 5A
					39 00 00 40 00 00 04 B0 00 3C B9
					39 00 00 40 00 00 03 B9 19 09
					39 00 00 40 00 00 04 B0 00 40 B9
					39 00 00 40 00 00 03 B9 33 33					/* TSP_VSYNC 0x33, 0x33 : Fixed TE; 0x30, 0x30 : G TE */
					39 00 00 40 00 00 04 B0 00 05 F2
					15 00 00 40 00 00 02 F2 C9
					15 00 00 40 00 00 02 F7 0F
					39 00 00 00 00 00 03 F0 A5 A5
					/* TSP_SYNC3 Fixed Setting */
					39 00 00 40 00 00 03 F0 5A 5A
					39 00 00 40 00 00 04 B0 00 06 F2
					15 00 00 40 00 00 02 F2 41
					39 00 00 40 00 00 04 B0 00 3E B9
					15 00 00 40 00 00 02 B9 09
					39 00 00 40 00 00 04 B0 00 42 B9
					15 00 00 40 00 00 02 B9 03
					39 00 00 40 00 00 04 B0 00 46 B9
					15 00 00 40 00 00 02 B9 00
					15 00 00 40 00 00 02 F7 0F
					39 00 00 00 79 00 03 F0 A5 A5
					/* Fixed TE Setting */
					39 00 00 40 00 00 03 F0 5A 5A
					15 00 00 40 00 00 02 B9 51
					39 00 00 40 00 00 04 B0 00 02 B9
					15 00 00 40 00 00 02 B9 00
					39 00 00 40 00 00 04 B0 00 08 B9
					39 00 00 40 00 00 09 B9 00 00 00 01 00 00 00 01
					39 00 00 00 79 00 03 F0 A5 A5

					/* 90hz Transition */
					39 00 00 40 00 00 03 F0 5A 5A
					15 00 00 40 00 00 02 AB 83
					39 00 00 40 00 00 04 B0 00 01 BD
					15 00 00 40 00 00 02 BD 02
					39 00 00 40 00 00 04 B0 00 08 F2
					39 00 00 40 00 00 04 F2 1C 00 14
					15 00 00 40 00 00 02 60 00
					15 00 00 40 00 00 02 F7 0F
					39 00 00 00 00 00 03 F0 A5 A5

					/* 120hz Transition */
					39 00 00 40 00 00 03 F0 5A 5A
					39 00 00 40 00 00 04 B0 00 17 F2
					39 00 00 40 00 00 03 F2 01 B5
					39 00 00 40 00 00 03 BD 21 02
					15 00 00 40 00 00 02 60 00
					39 00 00 40 00 00 04 B0 00 8C 94
					39 00 00 40 00 00 1F 94
						08 40 08 29 07 E2 07 B6
						07 53 06 EC 06 65 05 DB
						05 54 04 CD 04 4A 03 7C
						01 5E 01 5E 01 5E
					15 00 00 40 00 00 02 BD 23
					39 00 00 40 00 00 04 B0 00 10 BD
					15 00 00 40 00 00 02 BD 00
					39 00 00 40 00 00 04 B0 00 16 BD
					15 00 00 40 00 00 02 BD FF
					39 00 00 40 00 00 04 B0 00 14 BD
					15 00 00 40 00 00 02 BD 00
					15 00 00 40 00 00 02 F7 0F
					39 00 00 00 00 00 03 F0 A5 A5
				];
				qcom,mdss-dsi-on-command = [
					/* DSC Setting */
					39 00 00 00 00 00 5A 9E
						12 00 00 AB 30 80 0C 90
						05 A0 00 18 02 D0 02 D0
						02 00 02 86 00 20 02 83
						00 0A 00 0D 04 86 03 2E
						18 00 10 F0 07 10 20 00
						06 0F 0F 33 0E 1C 2A 38
						46 54 62 69 70 77 79 7B
						7D 7E 02 02 22 00 2A 40
						2A BE 3A FC 3A FA 3A F8
						3B 38 3B 78 3B B6 4B B6
						4B F4 4B F4 6C 34 84 74
						00
					15 00 00 00 00 00 02 9D 01

					/* Sleep Out(11h) */
					05 00 00 00 06 00 01 11

					/* TSP_SYNC1 Fixed Setting */
					39 00 00 40 00 00 03 F0 5A 5A
					39 00 00 40 00 00 04 B0 00 3C B9
					39 00 00 40 00 00 03 B9 19 09
					39 00 00 40 00 00 04 B0 00 40 B9
					39 00 00 40 00 00 03 B9 33 33					/* TSP_VSYNC 0x33, 0x33 : Fixed TE; 0x30, 0x30 : G TE */
					39 00 00 40 00 00 04 B0 00 05 F2
					15 00 00 40 00 00 02 F2 C9
					15 00 00 40 00 00 02 F7 0F
					39 00 00 00 00 00 03 F0 A5 A5
					/* TSP_SYNC3 Fixed Setting */
					39 00 00 40 00 00 03 F0 5A 5A
					39 00 00 40 00 00 04 B0 00 06 F2
					15 00 00 40 00 00 02 F2 41
					39 00 00 40 00 00 04 B0 00 3E B9
					15 00 00 40 00 00 02 B9 09
					39 00 00 40 00 00 04 B0 00 42 B9
					15 00 00 40 00 00 02 B9 03
					39 00 00 40 00 00 04 B0 00 46 B9
					15 00 00 40 00 00 02 B9 00
					15 00 00 40 00 00 02 F7 0F
					39 00 00 00 79 00 03 F0 A5 A5
					/* Fixed TE Setting */
					39 00 00 40 00 00 03 F0 5A 5A
					15 00 00 40 00 00 02 B9 51
					39 00 00 40 00 00 04 B0 00 02 B9
					15 00 00 40 00 00 02 B9 00
					39 00 00 40 00 00 04 B0 00 08 B9
					39 00 00 40 00 00 09 B9 00 00 00 01 00 00 00 01
					39 00 00 00 79 00 03 F0 A5 A5

					/* 90hz Transition */
					39 00 00 40 00 00 03 F0 5A 5A
					15 00 00 40 00 00 02 AB 83
					39 00 00 40 00 00 04 B0 00 01 BD
					15 00 00 40 00 00 02 BD 02
					39 00 00 40 00 00 04 B0 00 08 F2
					39 00 00 40 00 00 04 F2 1C 00 14
					15 00 00 40 00 00 02 60 00
					15 00 00 40 00 00 02 F7 0F
					39 00 00 00 00 00 03 F0 A5 A5

					/* 120hz Transition */
					39 00 00 40 00 00 03 F0 5A 5A
					39 00 00 40 00 00 04 B0 00 17 F2
					39 00 00 40 00 00 03 F2 01 B5
					39 00 00 40 00 00 03 BD 21 02
					15 00 00 40 00 00 02 60 00
					39 00 00 40 00 00 04 B0 00 8C 94
					39 00 00 40 00 00 1F 94
						08 40 08 29 07 E2 07 B6
						07 53 06 EC 06 65 05 DB
						05 54 04 CD 04 4A 03 7C
						01 5E 01 5E 01 5E
					15 00 00 40 00 00 02 BD 23
					39 00 00 40 00 00 04 B0 00 10 BD
					15 00 00 40 00 00 02 BD 00
					39 00 00 40 00 00 04 B0 00 16 BD
					15 00 00 40 00 00 02 BD FF
					39 00 00 40 00 00 04 B0 00 14 BD
					15 00 00 40 00 00 02 BD 00
					15 00 00 40 00 00 02 F7 0F
					39 00 00 00 00 00 03 F0 A5 A5

					/* Common Setting */
					39 00 00 40 00 00 03 F0 5A 5A
					39 00 00 40 00 00 03 F2 00 01					/* FQ_CON Setting */
					39 00 00 00 00 00 03 F0 A5 A5
					/* TE(Vsync) ON */
					39 00 00 40 00 00 03 F0 5A 5A
					15 00 00 40 00 00 02 35 00
					39 00 00 00 00 00 03 F0 A5 A5
					/* CASET/PASET Setting */
					39 00 00 00 00 00 05 2A 00 00 05 9F
					39 00 00 00 00 00 05 2B 00 00 0C 8F
					/* Scaler Setting */
					39 00 00 40 00 00 03 F0 5A 5A
					15 00 00 40 00 00 02 C3 00
					39 00 00 00 00 00 03 F0 A5 A5
					/* DCDC setting of AOD Sequence */
					39 00 00 40 00 00 03 F0 5A 5A
					39 00 00 40 00 00 04 B0 00 18 B1
					15 00 00 40 00 00 02 B1 05
					39 00 00 00 00 00 03 F0 A5 A5

					/* Brightness Control */
					39 00 00 40 00 00 03 F0 5A 5A
					39 00 00 40 00 00 04 B0 00 10 94
					15 00 00 40 00 00 02 94 01
					39 00 00 40 00 00 04 B0 00 0F 94
					15 00 00 40 00 00 02 94 90
					39 00 00 40 00 00 03 F0 A5 A5
					15 00 00 40 00 00 02 53 28
					15 00 00 00 00 00 02 F7 0F
					/* ACL Mode */
					39 00 00 40 00 00 03 F0 5A 5A
					39 00 00 40 00 00 04 B0 00 01 94
					15 00 00 40 00 00 02 94 0D
					15 00 00 40 00 00 02 55 00
					39 00 00 00 00 00 03 F0 A5 A5
					/* OPEC Setting */
					39 00 00 40 00 00 03 F0 5A 5A
					39 00 00 40 00 00 04 B0 00 1D 63
					15 00 00 40 00 00 02 63 02
					39 00 00 00 00 00 03 F0 A5 A5
					/* Display On */
					05 00 00 00 00 00 01 29
				];

				qcom,mdss-dsi-qsync-on-commands = [
					/* SDC Auto On */
					39 00 00 40 00 00 03 F0 5A 5A
					15 00 00 40 00 00 02 BD 23
					39 00 00 40 00 00 04 B0 00 10 BD
					15 00 00 40 00 00 02 BD 10
					39 00 00 40 00 00 04 B0 00 16 BD
					15 00 00 40 00 00 02 BD 03
					15 00 00 40 00 00 02 F7 0F
					39 00 00 00 00 00 03 F0 A5 A5
				];
				qcom,mdss-dsi-qsync-off-commands = [
					/* SDC Auto Off */
					39 00 00 40 00 00 03 F0 5A 5A
					15 00 00 40 00 00 02 BD 23
					39 00 00 40 00 00 04 B0 00 10 BD
					15 00 00 40 00 00 02 BD 00
					39 00 00 40 00 00 04 B0 00 16 BD
					15 00 00 40 00 00 02 BD FF
					15 00 00 40 00 00 02 F7 0F
					39 00 00 00 00 00 03 F0 A5 A5
				];
				qcom,mdss-dsi-qsync-min-fps-0-command = [
					/* SDC Auto Off */
					39 00 00 40 00 00 03 F0 5A 5A
					39 00 00 40 00 00 04 B0 00 14 BD
					15 00 00 40 00 00 02 BD 00
					39 00 00 40 00 00 04 B0 00 13 BD
					15 00 00 40 00 00 02 BD 00
					15 00 00 40 00 00 02 F7 0F
					39 00 00 00 00 00 03 F0 A5 A5
				];
				qcom,mdss-dsi-qsync-min-fps-1-command = [
					/* SDC Auto On */
					39 00 00 40 00 00 03 F0 5A 5A
					39 00 00 40 00 00 04 B0 00 14 BD
					15 00 00 40 00 00 02 BD 00
					39 00 00 40 00 00 04 B0 00 13 BD
					15 00 00 40 00 00 02 BD 00
					15 00 00 40 00 00 02 F7 0F
					39 00 00 00 00 00 03 F0 A5 A5
				];

				qcom,mdss-dsi-fakeframe-command-state = "dsi_hs_mode";
				qcom,mdss-dsi-qsync-on-commands-state ="dsi_hs_mode";
				qcom,mdss-dsi-qsync-off-commands-state ="dsi_hs_mode";
				qcom,mdss-dsi-qsync-min-fps-0-command-state = "dsi_hs_mode";
				qcom,mdss-dsi-qsync-min-fps-1-command-state = "dsi_hs_mode";
				qcom,panel-roi-alignment=<1440 24 1440 24 1440 24>;
				qcom,partial-update-enabled = "single_roi";

				qcom,lm-split = <720 720>;
				qcom,mdss-dsc-slice-height = <24>;
				qcom,mdss-dsc-slice-width = <720>;
			};

			timing@wqhd_sdc_90 {
				qcom,mdss-mdp-transfer-time-us = <7700>;
				qcom,mdss-dsi-panel-framerate = <90>;
				qcom,mdss-dsi-panel-clockrate = <1372000000>;
				qcom,mdss-dsi-panel-width = <1440>;
				qcom,mdss-dsi-panel-height = <3216>;
				qcom,mdss-dsi-h-front-porch = <88>;
				qcom,mdss-dsi-h-back-porch = <57>;
				qcom,mdss-dsi-h-pulse-width = <8>;
				qcom,mdss-dsi-h-sync-pulse = <0>;
				qcom,mdss-dsi-v-back-porch = <8>;
				qcom,mdss-dsi-v-front-porch = <8>;
				qcom,mdss-dsi-v-pulse-width = <8>;

				/* SDC ADFR */
				qcom,mdss-dsi-h-sync-skew = <0>;
				oplus,adfr-fakeframe-config = <3>;
				oplus,adfr-fakeframe-deferred-time = <6>;		/* period*0.7 */
				qcom,mdss-dsi-qsync-min-fps-0 = <1314>;
				qcom,mdss-dsi-qsync-min-fps-1 = <1314>;
				qcom,mdss-dsi-fakeframe-command = [
					05 00 00 40 00 00 01 2C
					05 00 00 40 00 00 01 3C
					05 00 00 40 00 00 01 2C
					05 00 00 40 00 00 01 3C
					05 00 00 00 00 00 01 00
				];

				qcom,mdss-dsi-adfr-pre-switch-command = [
					39 00 00 40 00 00 03 F0 5A 5A					/* Level2 key Access Enable */
					39 00 00 40 00 00 04 B0 00 14 BD
					15 00 00 40 00 00 02 BD 00						/* SDC auto mode min == max */
					15 00 00 40 00 00 02 BD 23						/* 21 : Manual On  23 Auto On */
					15 00 00 40 00 00 02 F7 0F
					39 00 00 00 00 00 03 F0 A5 A5					/* Level2 key Access Disable */
				];

				qcom,mdss-dsi-timing-switch-command = [
					/* CASET/PASET Setting */
					39 00 00 00 00 00 05 2A 00 00 05 9F
					39 00 00 00 00 00 05 2B 00 00 0C 8F
					/* Scaler Setting */
					39 00 00 40 00 00 03 F0 5A 5A
					15 00 00 40 00 00 02 C3 00
					39 00 00 00 00 00 03 F0 A5 A5

					/* TSP_SYNC1 Fixed Setting */
					39 00 00 40 00 00 03 F0 5A 5A
					39 00 00 40 00 00 04 B0 00 3C B9
					39 00 00 40 00 00 03 B9 19 09
					39 00 00 40 00 00 04 B0 00 40 B9
					39 00 00 40 00 00 03 B9 33 33					/* TSP_VSYNC 0x33, 0x33 : Fixed TE; 0x30, 0x30 : G TE */
					39 00 00 40 00 00 04 B0 00 05 F2
					15 00 00 40 00 00 02 F2 C9
					15 00 00 40 00 00 02 F7 0F
					39 00 00 00 00 00 03 F0 A5 A5
					/* TSP_SYNC3 Fixed Setting */
					39 00 00 40 00 00 03 F0 5A 5A
					39 00 00 40 00 00 04 B0 00 06 F2
					15 00 00 40 00 00 02 F2 41
					39 00 00 40 00 00 04 B0 00 3E B9
					15 00 00 40 00 00 02 B9 09
					39 00 00 40 00 00 04 B0 00 42 B9
					15 00 00 40 00 00 02 B9 03
					39 00 00 40 00 00 04 B0 00 46 B9
					15 00 00 40 00 00 02 B9 00
					15 00 00 40 00 00 02 F7 0F
					39 00 00 00 79 00 03 F0 A5 A5

					/* 120hz Transition */
					39 00 00 40 00 00 03 F0 5A 5A
					39 00 00 40 00 00 04 B0 00 17 F2
					39 00 00 40 00 00 03 F2 01 B5
					39 00 00 40 00 00 03 BD 21 02
					15 00 00 40 00 00 02 60 00
					39 00 00 40 00 00 04 B0 00 8C 94
					39 00 00 40 00 00 1F 94 08 40 08 29 07 E2 07 B6 07 53 06 EC 06 65 05 DB 05 54 04 CD 04 4A 03 7C 01 5E 01 5E 01 5E
					15 00 00 40 00 00 02 F7 0F
					39 00 00 00 00 00 03 F0 A5 A5

					/* 90hz Transition */
					39 00 00 40 00 00 03 F0 5A 5A
					15 00 00 40 00 00 02 AB 83
					39 00 00 40 00 00 04 B0 00 01 BD
					15 00 00 40 00 00 02 BD 03
					39 00 00 40 00 00 04 B0 00 08 F2
					39 00 00 40 00 00 04 F2 1C 04 54
					15 00 00 40 00 00 02 60 08
					15 00 00 40 00 00 02 F7 0F
					39 00 00 00 00 00 03 F0 A5 A5
				];
				qcom,mdss-dsi-on-command = [
					/* DSC Setting */
					39 00 00 00 00 00 5A 9E
						12 00 00 AB 30 80 0C 90
						05 A0 00 18 02 D0 02 D0
						02 00 02 86 00 20 02 83
						00 0A 00 0D 04 86 03 2E
						18 00 10 F0 07 10 20 00
						06 0F 0F 33 0E 1C 2A 38
						46 54 62 69 70 77 79 7B
						7D 7E 02 02 22 00 2A 40
						2A BE 3A FC 3A FA 3A F8
						3B 38 3B 78 3B B6 4B B6
						4B F4 4B F4 6C 34 84 74
						00
					15 00 00 00 00 00 02 9D 01

					/* Sleep Out(11h) */
					05 00 00 00 06 00 01 11

					/* TSP_SYNC1 Fixed Setting */
					39 00 00 40 00 00 03 F0 5A 5A
					39 00 00 40 00 00 04 B0 00 3C B9
					39 00 00 40 00 00 03 B9 19 09
					39 00 00 40 00 00 04 B0 00 40 B9
					39 00 00 40 00 00 03 B9 33 33					/* TSP_VSYNC 0x33, 0x33 : Fixed TE; 0x30, 0x30 : G TE */
					39 00 00 40 00 00 04 B0 00 05 F2
					15 00 00 40 00 00 02 F2 C9
					15 00 00 40 00 00 02 F7 0F
					39 00 00 00 00 00 03 F0 A5 A5
					/* TSP_SYNC3 Fixed Setting */
					39 00 00 40 00 00 03 F0 5A 5A
					39 00 00 40 00 00 04 B0 00 06 F2
					15 00 00 40 00 00 02 F2 41
					39 00 00 40 00 00 04 B0 00 3E B9
					15 00 00 40 00 00 02 B9 09
					39 00 00 40 00 00 04 B0 00 42 B9
					15 00 00 40 00 00 02 B9 03
					39 00 00 40 00 00 04 B0 00 46 B9
					15 00 00 40 00 00 02 B9 00
					15 00 00 40 00 00 02 F7 0F
					39 00 00 00 79 00 03 F0 A5 A5

					/* 120hz Transition */
					39 00 00 40 00 00 03 F0 5A 5A
					39 00 00 40 00 00 04 B0 00 17 F2
					39 00 00 40 00 00 03 F2 01 B5
					39 00 00 40 00 00 03 BD 21 02
					15 00 00 40 00 00 02 60 00
					39 00 00 40 00 00 04 B0 00 8C 94
					39 00 00 40 00 00 1F 94 08 40 08 29 07 E2 07 B6 07 53 06 EC 06 65 05 DB 05 54 04 CD 04 4A 03 7C 01 5E 01 5E 01 5E
					15 00 00 40 00 00 02 F7 0F
					39 00 00 00 00 00 03 F0 A5 A5

					/* 90hz Transition */
					39 00 00 40 00 00 03 F0 5A 5A
					15 00 00 40 00 00 02 AB 83
					39 00 00 40 00 00 04 B0 00 01 BD
					15 00 00 40 00 00 02 BD 03
					39 00 00 40 00 00 04 B0 00 08 F2
					39 00 00 40 00 00 04 F2 1C 04 54
					15 00 00 40 00 00 02 60 08
					15 00 00 40 00 00 02 F7 0F
					39 00 00 00 00 00 03 F0 A5 A5

					/* Common Setting */
					39 00 00 40 00 00 03 F0 5A 5A
					39 00 00 40 00 00 03 F2 00 01					/* FQ_CON Setting */
					39 00 00 00 00 00 03 F0 A5 A5
					/* TE(Vsync) ON */
					39 00 00 40 00 00 03 F0 5A 5A
					15 00 00 40 00 00 02 35 00
					39 00 00 00 00 00 03 F0 A5 A5
					/* CASET/PASET Setting */
					39 00 00 00 00 00 05 2A 00 00 05 9F
					39 00 00 00 00 00 05 2B 00 00 0C 8F
					/* Scaler Setting */
					39 00 00 40 00 00 03 F0 5A 5A
					15 00 00 40 00 00 02 C3 00
					39 00 00 00 00 00 03 F0 A5 A5
					/* DCDC setting of AOD Sequence */
					39 00 00 40 00 00 03 F0 5A 5A
					39 00 00 40 00 00 04 B0 00 18 B1
					15 00 00 40 00 00 02 B1 05
					39 00 00 00 00 00 03 F0 A5 A5

					/* Brightness Control */
					39 00 00 40 00 00 03 F0 5A 5A
					39 00 00 40 00 00 04 B0 00 10 94
					15 00 00 40 00 00 02 94 01
					39 00 00 40 00 00 04 B0 00 0F 94
					15 00 00 40 00 00 02 94 90
					39 00 00 40 00 00 03 F0 A5 A5
					15 00 00 40 00 00 02 53 28
					15 00 00 00 00 00 02 F7 0F
					/* ACL Mode */
					39 00 00 40 00 00 03 F0 5A 5A
					39 00 00 40 00 00 04 B0 00 01 94
					15 00 00 40 00 00 02 94 0D
					15 00 00 40 00 00 02 55 00
					39 00 00 00 00 00 03 F0 A5 A5
					/* OPEC Setting */
					39 00 00 40 00 00 03 F0 5A 5A
					39 00 00 40 00 00 04 B0 00 1D 63
					15 00 00 40 00 00 02 63 02
					39 00 00 00 00 00 03 F0 A5 A5
					/* Display On */
					05 00 00 00 00 00 01 29
				];

				qcom,mdss-dsi-post-on-backlight = [
					/* Display On */
					05 00 00 00 00 00 01 29
				];
				qcom,mdss-dsi-off-command = [
					/* Display Off */
					05 00 00 00 15 00 02 28 00
					/* Sleep In */
					05 00 00 00 65 00 02 10 00
				];

				qcom,mdss-dsi-qsync-on-commands = [
				];
				qcom,mdss-dsi-qsync-off-commands = [
				];
				qcom,mdss-dsi-qsync-min-fps-0-command = [
				];
				qcom,mdss-dsi-qsync-min-fps-1-command = [
				];

				qcom,mdss-dsi-fakeframe-command-state = "dsi_hs_mode";
				qcom,mdss-dsi-adfr-pre-switch-command-state = "dsi_hs_mode";
				qcom,mdss-dsi-timing-switch-command-state = "dsi_hs_mode";
				qcom,mdss-dsi-qsync-on-commands-state ="dsi_hs_mode";
				qcom,mdss-dsi-qsync-off-commands-state ="dsi_hs_mode";
				qcom,mdss-dsi-qsync-min-fps-0-command-state = "dsi_hs_mode";
				qcom,mdss-dsi-qsync-min-fps-1-command-state = "dsi_hs_mode";
				qcom,panel-roi-alignment=<1440 24 1440 24 1440 24>;
				qcom,partial-update-enabled = "single_roi";

				qcom,compression-mode = "dsc";
				qcom,mdss-dsc-encoders = <2>;
				qcom,mdss-dsc-slice-per-pkt = <2>;
				qcom,mdss-dsc-bit-per-component = <10>;
				qcom,mdss-dsc-bit-per-pixel = <8>;
				qcom,mdss-dsc-version = <0x12>;
				//qcom,mdss-dsc-scr-version = <1>;
				qcom,mdss-dsc-block-prediction-enable;
				qcom,lm-split = <720 720>;
				qcom,mdss-dsc-slice-height = <24>;
				qcom,mdss-dsc-slice-width = <720>;
			};

			timing@wqhd_sdc_60 {
				#include "dsi-panel-samsung-amb670yf09-1440-3216-dsc-60fps-cmd-common.dtsi"
				qcom,mdss-mdp-transfer-time-us = <7700>;
				qcom,mdss-dsi-panel-framerate = <60>;
				qcom,mdss-dsi-panel-clockrate = <1372000000>;
				qcom,mdss-dsi-panel-width = <1440>;
				qcom,mdss-dsi-panel-height = <3216>;
				qcom,mdss-dsi-h-front-porch = <88>;
				qcom,mdss-dsi-h-back-porch = <56>;
				qcom,mdss-dsi-h-pulse-width = <8>;
				qcom,mdss-dsi-h-sync-pulse = <0>;
				qcom,mdss-dsi-v-back-porch = <8>;
				qcom,mdss-dsi-v-front-porch = <8>;
				qcom,mdss-dsi-v-pulse-width = <8>;

				/* SDC ADFR */
				qcom,mdss-dsi-h-sync-skew = <1>;
				oplus,adfr-fakeframe-config = <3>;
				oplus,adfr-fakeframe-deferred-time = <6>;		/* period*0.7 */
				qcom,mdss-dsi-qsync-min-fps-0 = <1314>;
				qcom,mdss-dsi-qsync-min-fps-1 = <1314>;
				qcom,mdss-dsi-fakeframe-command = [
					05 00 00 40 00 00 01 2C
					05 00 00 40 00 00 01 3C
					05 00 00 40 00 00 01 2C
					05 00 00 40 00 00 01 3C
					05 00 00 00 00 00 01 00
				];

				qcom,mdss-dsi-timing-switch-command = [
					/* CASET/PASET Setting */
					39 00 00 00 00 00 05 2A 00 00 05 9F
					39 00 00 00 00 00 05 2B 00 00 0C 8F
					/* Scaler Setting */
					39 00 00 40 00 00 03 F0 5A 5A
					15 00 00 40 00 00 02 C3 00
					39 00 00 00 00 00 03 F0 A5 A5

					/* TSP_SYNC1 Fixed Setting */
					39 00 00 40 00 00 03 F0 5A 5A
					39 00 00 40 00 00 04 B0 00 3C B9
					39 00 00 40 00 00 03 B9 19 09
					39 00 00 40 00 00 04 B0 00 40 B9
					39 00 00 40 00 00 03 B9 33 33					/* TSP_VSYNC 0x33, 0x33 : Fixed TE; 0x30, 0x30 : G TE */
					39 00 00 40 00 00 04 B0 00 05 F2
					15 00 00 40 00 00 02 F2 C9
					15 00 00 40 00 00 02 F7 0F
					39 00 00 00 00 00 03 F0 A5 A5
					/* TSP_SYNC3 Fixed Setting */
					39 00 00 40 00 00 03 F0 5A 5A
					39 00 00 40 00 00 04 B0 00 06 F2
					15 00 00 40 00 00 02 F2 41
					39 00 00 40 00 00 04 B0 00 3E B9
					15 00 00 40 00 00 02 B9 09
					39 00 00 40 00 00 04 B0 00 42 B9
					15 00 00 40 00 00 02 B9 03
					39 00 00 40 00 00 04 B0 00 46 B9
					15 00 00 40 00 00 02 B9 01
					15 00 00 40 00 00 02 F7 0F
					39 00 00 00 79 00 03 F0 A5 A5
					/* Fixed TE Setting */
					39 00 00 40 00 00 03 F0 5A 5A
					15 00 00 40 00 00 02 B9 51
					39 00 00 40 00 00 04 B0 00 02 B9
					15 00 00 40 00 00 02 B9 01
					39 00 00 40 00 00 04 B0 00 08 B9
					39 00 00 40 00 00 09 B9 00 00 00 01 00 00 00 01
					39 00 00 00 79 00 03 F0 A5 A5

					/* 90hz Transition */
					39 00 00 40 00 00 03 F0 5A 5A
					15 00 00 40 00 00 02 AB 83
					39 00 00 40 00 00 04 B0 00 01 BD
					15 00 00 40 00 00 02 BD 02
					39 00 00 40 00 00 04 B0 00 08 F2
					39 00 00 40 00 00 04 F2 1C 00 14
					15 00 00 40 00 00 02 60 00
					15 00 00 40 00 00 02 F7 0F
					39 00 00 00 00 00 03 F0 A5 A5

					/* 60hz Transition */
					39 00 00 40 00 00 03 F0 5A 5A
					39 00 00 40 00 00 04 B0 00 17 F2
					39 00 00 40 00 00 03 F2 01 B5
					39 00 00 40 00 00 03 BD 21 02
					15 00 00 40 00 00 02 60 01
					39 00 00 40 00 00 04 B0 00 8C 94
					39 00 00 40 00 00 1F 94 08 40 08 29 07 E2 07 B6 07 53 06 EC 06 65 05 DB 05 54 04 CD 04 4A 03 7C 01 5E 01 5E 01 5E
					15 00 00 40 00 00 02 BD 23
					39 00 00 40 00 00 04 B0 00 10 BD
					15 00 00 40 00 00 02 BD 00
					39 00 00 40 00 00 04 B0 00 16 BD
					15 00 00 40 00 00 02 BD FF
					39 00 00 40 00 00 04 B0 00 14 BD
					15 00 00 40 00 00 02 BD 01
					15 00 00 40 00 00 02 F7 0F
					39 00 00 00 00 00 03 F0 A5 A5
				];
				qcom,mdss-dsi-on-command = [
					/* DSC Setting */
					39 00 00 00 00 00 5A 9E
						12 00 00 AB 30 80 0C 90
						05 A0 00 18 02 D0 02 D0
						02 00 02 86 00 20 02 83
						00 0A 00 0D 04 86 03 2E
						18 00 10 F0 07 10 20 00
						06 0F 0F 33 0E 1C 2A 38
						46 54 62 69 70 77 79 7B
						7D 7E 02 02 22 00 2A 40
						2A BE 3A FC 3A FA 3A F8
						3B 38 3B 78 3B B6 4B B6
						4B F4 4B F4 6C 34 84 74
						00
					15 00 00 00 00 00 02 9D 01

					/* Sleep Out(11h) */
					05 00 00 00 06 00 01 11

					/* TSP_SYNC1 Fixed Setting */
					39 00 00 40 00 00 03 F0 5A 5A
					39 00 00 40 00 00 04 B0 00 3C B9
					39 00 00 40 00 00 03 B9 19 09
					39 00 00 40 00 00 04 B0 00 40 B9
					39 00 00 40 00 00 03 B9 33 33					/* TSP_VSYNC 0x33, 0x33 : Fixed TE; 0x30, 0x30 : G TE */
					39 00 00 40 00 00 04 B0 00 05 F2
					15 00 00 40 00 00 02 F2 C9
					15 00 00 40 00 00 02 F7 0F
					39 00 00 00 00 00 03 F0 A5 A5
					/* TSP_SYNC3 Fixed Setting */
					39 00 00 40 00 00 03 F0 5A 5A
					39 00 00 40 00 00 04 B0 00 06 F2
					15 00 00 40 00 00 02 F2 41
					39 00 00 40 00 00 04 B0 00 3E B9
					15 00 00 40 00 00 02 B9 09
					39 00 00 40 00 00 04 B0 00 42 B9
					15 00 00 40 00 00 02 B9 03
					39 00 00 40 00 00 04 B0 00 46 B9
					15 00 00 40 00 00 02 B9 01
					15 00 00 40 00 00 02 F7 0F
					39 00 00 00 79 00 03 F0 A5 A5
					/* Fixed TE Setting */
					39 00 00 40 00 00 03 F0 5A 5A
					15 00 00 40 00 00 02 B9 51
					39 00 00 40 00 00 04 B0 00 02 B9
					15 00 00 40 00 00 02 B9 01
					39 00 00 40 00 00 04 B0 00 08 B9
					39 00 00 40 00 00 09 B9 00 00 00 01 00 00 00 01
					39 00 00 00 79 00 03 F0 A5 A5

					/* 90hz Transition */
					39 00 00 40 00 00 03 F0 5A 5A
					15 00 00 40 00 00 02 AB 83
					39 00 00 40 00 00 04 B0 00 01 BD
					15 00 00 40 00 00 02 BD 02
					39 00 00 40 00 00 04 B0 00 08 F2
					39 00 00 40 00 00 04 F2 1C 00 14
					15 00 00 40 00 00 02 60 00
					15 00 00 40 00 00 02 F7 0F
					39 00 00 00 00 00 03 F0 A5 A5

					/* 60hz Transition */
					39 00 00 40 00 00 03 F0 5A 5A
					39 00 00 40 00 00 04 B0 00 17 F2
					39 00 00 40 00 00 03 F2 01 B5
					39 00 00 40 00 00 03 BD 21 02
					15 00 00 40 00 00 02 60 01
					39 00 00 40 00 00 04 B0 00 8C 94
					39 00 00 40 00 00 1F 94 08 40 08 29 07 E2 07 B6 07 53 06 EC 06 65 05 DB 05 54 04 CD 04 4A 03 7C 01 5E 01 5E 01 5E
					15 00 00 40 00 00 02 BD 23
					39 00 00 40 00 00 04 B0 00 10 BD
					15 00 00 40 00 00 02 BD 00
					39 00 00 40 00 00 04 B0 00 16 BD
					15 00 00 40 00 00 02 BD FF
					39 00 00 40 00 00 04 B0 00 14 BD
					15 00 00 40 00 00 02 BD 01
					15 00 00 40 00 00 02 F7 0F
					39 00 00 00 00 00 03 F0 A5 A5

					/* Common Setting */
					39 00 00 40 00 00 03 F0 5A 5A
					39 00 00 40 00 00 03 F2 00 01					/* FQ_CON Setting */
					39 00 00 00 00 00 03 F0 A5 A5
					/* TE(Vsync) ON */
					39 00 00 40 00 00 03 F0 5A 5A
					15 00 00 40 00 00 02 35 00
					39 00 00 00 00 00 03 F0 A5 A5
					/* CASET/PASET Setting */
					39 00 00 00 00 00 05 2A 00 00 05 9F
					39 00 00 00 00 00 05 2B 00 00 0C 8F
					/* Scaler Setting */
					39 00 00 40 00 00 03 F0 5A 5A
					15 00 00 40 00 00 02 C3 00
					39 00 00 00 00 00 03 F0 A5 A5
					/* DCDC setting of AOD Sequence */
					39 00 00 40 00 00 03 F0 5A 5A
					39 00 00 40 00 00 04 B0 00 18 B1
					15 00 00 40 00 00 02 B1 05
					39 00 00 00 00 00 03 F0 A5 A5

					/* Brightness Control */
					39 00 00 40 00 00 03 F0 5A 5A
					39 00 00 40 00 00 04 B0 00 10 94
					15 00 00 40 00 00 02 94 01
					39 00 00 40 00 00 04 B0 00 0F 94
					15 00 00 40 00 00 02 94 90
					39 00 00 40 00 00 03 F0 A5 A5
					15 00 00 40 00 00 02 53 28
					15 00 00 00 00 00 02 F7 0F
					/* ACL Mode */
					39 00 00 40 00 00 03 F0 5A 5A
					39 00 00 40 00 00 04 B0 00 01 94
					15 00 00 40 00 00 02 94 0D
					15 00 00 40 00 00 02 55 00
					39 00 00 00 00 00 03 F0 A5 A5
					/* OPEC Setting */
					39 00 00 40 00 00 03 F0 5A 5A
					39 00 00 40 00 00 04 B0 00 1D 63
					15 00 00 40 00 00 02 63 02
					39 00 00 00 00 00 03 F0 A5 A5
					/* Display On */
					05 00 00 00 00 00 01 29
				];

				qcom,mdss-dsi-qsync-on-commands = [
				];
				qcom,mdss-dsi-qsync-off-commands = [
					/* SDC Auto Off */
					39 00 00 40 00 00 03 F0 5A 5A
					15 00 00 40 00 00 02 BD 23
					39 00 00 40 00 00 04 B0 00 10 BD
					15 00 00 40 00 00 02 BD 00
					39 00 00 40 00 00 04 B0 00 16 BD
					15 00 00 40 00 00 02 BD FF
					15 00 00 40 00 00 02 F7 0F
					39 00 00 00 00 00 03 F0 A5 A5
				];
				qcom,mdss-dsi-qsync-min-fps-0-command = [
					/* SDC Auto Off */
					39 00 00 40 00 00 03 F0 5A 5A
					39 00 00 40 00 00 04 B0 00 14 BD
					15 00 00 40 00 00 02 BD 00
					39 00 00 40 00 00 04 B0 00 13 BD
					15 00 00 40 00 00 02 BD 00
					15 00 00 40 00 00 02 F7 0F
					39 00 00 00 00 00 03 F0 A5 A5
				];

				qcom,mdss-dsi-fakeframe-command-state = "dsi_hs_mode";
				qcom,mdss-dsi-qsync-on-commands-state ="dsi_hs_mode";
				qcom,mdss-dsi-qsync-off-commands-state ="dsi_hs_mode";
				qcom,mdss-dsi-qsync-min-fps-0-command-state = "dsi_hs_mode";
				qcom,mdss-dsi-qsync-min-fps-1-command-state = "dsi_hs_mode";
				qcom,panel-roi-alignment=<1440 24 1440 24 1440 24>;
				qcom,partial-update-enabled = "single_roi";

				qcom,lm-split = <720 720>;
				qcom,mdss-dsc-slice-height = <24>;
				qcom,mdss-dsc-slice-width = <720>;
			};
		};
	};
};

&dsi_panel_samsung_amb670yf09_1440_3216_dsc_cmd {
	qcom,ulps-enabled;
	qcom,dsi-select-clocks = "pll_byte_clk0", "pll_dsi_clk0";
	qcom,mdss-dsi-display-timings {
		timing@fhd_sdc_120 {
			qcom,mdss-dsi-panel-phy-timings = [00 1C 07 07 17 22 07 07 08 02 04 00 18 0C];
			qcom,display-topology = <1 1 1>,<2 2 1>;
			qcom,default-topology-index = <1>;
		};
		timing@fhd_sdc_90 {
			qcom,mdss-dsi-panel-phy-timings = [00 1C 07 07 17 22 07 07 08 02 04 00 18 0C];
			qcom,display-topology = <1 1 1>,<2 2 1>;
			qcom,default-topology-index = <1>;
		};
		timing@fhd_sdc_60 {
			qcom,mdss-dsi-panel-phy-timings = [00 1C 07 07 17 22 07 07 08 02 04 00 18 0C];
			qcom,display-topology = <1 1 1>,<2 2 1>;
			qcom,default-topology-index = <1>;
		};
		timing@wqhd_sdc_120 {
			qcom,mdss-dsi-panel-phy-timings = [00 2C 0C 0C 1D 27 09 0C 0B 02 04 00 24 11];
			qcom,display-topology = <1 1 1>,<2 2 1>;
			qcom,default-topology-index = <1>;
		};
		timing@wqhd_sdc_90 {
			qcom,mdss-dsi-panel-phy-timings = [00 2C 0C 0C 1D 27 09 0C 0B 02 04 00 24 11];
			qcom,display-topology = <1 1 1>,<2 2 1>;
			qcom,default-topology-index = <1>;
		};
		timing@wqhd_sdc_60 {
			qcom,mdss-dsi-panel-phy-timings = [00 2C 0C 0C 1D 27 09 0C 0B 02 04 00 24 11];
			qcom,display-topology = <1 1 1>,<2 2 1>;
			qcom,default-topology-index = <1>;
		};
	};
};

&dsi_panel_samsung_amb670yf09_1440_3216_dsc_cmd {
	/* HARDWARE CONFIG */
	qcom,panel-supply-entries = <&dsi_panel_pwr_supply>;
	qcom,mdss-dsi-bl-pmic-control-type = "bl_ctrl_dcs";
	qcom,mdss-dsi-panel-controller = <&mdss_dsi0>;
	qcom,platform-te-gpio = <&tlmm 86 0>;
	qcom,platform-te-gpio-1 = <&tlmm 87 0>;
	qcom,dynamic-te-gpio = <&tlmm 88 0>;
	qcom,platform-reset-gpio = <&tlmm 133 0>;
	qcom,platform-panel-vout-gpio = <&tlmm 90 0>;
	//qcom,platform-panel-vddr-aod-en-gpio = <&tlmm 180 0>;
	qcom,panel_voltage_vddi_name = "vddio";
	qcom,panel_voltage_vddi = <0 1800000 1850000 1950000>;
	qcom,panel_voltage_vddr_name = "vddio";
	qcom,panel_voltage_vddr = <1 1800000 1850000 1950000>;

	/* BRIGHTNESS CONFIG */
	qcom,bl-dsc-cmd-state = "dsi_hs_mode";
	qcom,mdss-dsi-bl-inverted-dbv;
	qcom,mdss-dsi-bl-min-level = <1>;
	qcom,mdss-dsi-bl-max-level = <4095>;
	qcom,mdss-brightness-max-level = <4095>;
	oplus,dsi-bl-normal-max-level = <2047>;
	oplus,dsi-brightness-default-level = <1433>;
	oplus,dsi-brightness-normal-max-level = <2047>;
	oplus,dsi-dc-backlight-threshold = <1037>;
	oplus,dsi-global-hbm-case-id = <1>;
	//oplus,dsi-global-hbm-case23-threshold = <2048>;

	/* ESD CONFIG */
	qcom,esd-check-enabled;
	qcom,mdss-dsi-panel-status-check-mode = "reg_read";
	qcom,mdss-dsi-panel-status-command = [06 00 00 00 00 00 01 0A];
	qcom,mdss-dsi-panel-status-command-state = "dsi_lp_mode";
	qcom,mdss-dsi-panel-status-value = <0x9F 0x9D>;
	qcom,mdss-dsi-panel-status-read-length = <1>;
	oplus,mdss-dsi-panel-status-match-modes = <0x00000000>;

	/* FACTORY CONFIG */
	oplus,mdss-dsi-vendor-name = "S6E3HC4";
	oplus,mdss-dsi-manufacture = "samsung1024";
	oplus,color_vivid_status;
	oplus,color_srgb_status;
	oplus,apollo_backlight_enable;
	oplus,color_oplus_calibrate_status;
	oplus,color_dual_brightness_status;

	/* OPLUS FEATURES CONFIG */
	oplus,dp-enabled;
	//oplus,dsi-cabc-enabled;
	//oplus,dsi-dre-enabled;
	oplus,dsi-serial-number-enabled;
	//oplus,dsi-serial-number-lock;
	oplus,dsi-serial-number-reg= <0xA1>;
	oplus,dsi-serial-number-index= <4>;
	oplus,dsi-serial-number-read-count= <11>;

	/* ADFR CONFIG */
	qcom,qsync-enable;
	qcom,mdss-dsi-qsync-min-refresh-rate = <24>;
	/*
	** 0st bit: adfr global on/off
	** 1st bit: fakeframe on/off
	** 2st bit: switch on/off
	** 3rd bit: 0:double-TE switch 1:external TE/TP switch
	** 4rd bit: idle mode on/off
	*/
	oplus,adfr-config = <21>;

	/* AOD/FOD CONFIG */
	oplus,ofp-config = <01>;
	oplus,dsi-ofp-brightness = <0 0xFF>,
			<2 0xF2>,
			<4 0xED>,
			<6 0xEC>,
			<8 0xEA>,
			<10 0xE9>,
			<20 0xE4>,
			<40 0xDC>,
			<60 0xD4>,
			<90 0xCA>,
			<140 0xC0>,
			<200 0xB4>,
			<300 0xA4>,
			<450 0x93>,
			<600 0x81>,
			<750 0x77>,
			<900 0x69>,
			<1050 0x60>,
			<1200 0x54>,
			<1400 0x49>,
			<1600 0x3C>,
			<1800 0x32>,
			<2047 0x24>;
	oplus,dsi-dc-brightness = <0 0xFF>,
			<2 0xFC>,
			<4 0xF9>,
			<6 0xF9>,
			<8 0xF8>,
			<10 0xF7>,
			<15 0xF6>,
			<20 0xF4>,
			<30 0xF0>,
			<40 0xEB>,
			<50 0xE6>,
			<60 0xE1>,
			<70 0xDD>,
			<80 0xD8>,
			<100 0xCF>,
			<120 0xC5>,
			<150 0xB9>,
			<200 0xA2>,
			<250 0x8C>,
			<300 0x76>,
			<350 0x5B>,
			<400 0x44>,
			<450 0x2C>,
			<500 0x0D>,
			<520 0x00>;
};

